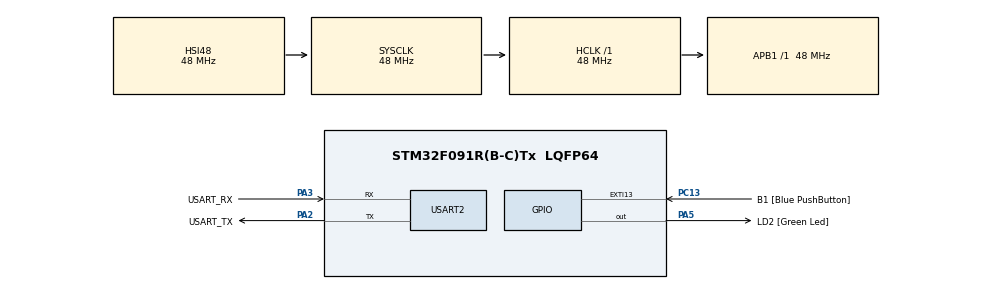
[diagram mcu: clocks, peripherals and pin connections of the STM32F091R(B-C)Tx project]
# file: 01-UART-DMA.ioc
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Dma.MEMTOMEM.1.Direction=DMA_MEMORY_TO_MEMORY
Dma.MEMTOMEM.1.Instance=DMA2_Channel1
Dma.MEMTOMEM.1.MemDataAlignment=DMA_MDATAALIGN_BYTE
Dma.MEMTOMEM.1.MemInc=DMA_MINC_ENABLE
Dma.MEMTOMEM.1.Mode=DMA_NORMAL
Dma.MEMTOMEM.1.PeriphDataAlignment=DMA_PDATAALIGN_BYTE
Dma.MEMTOMEM.1.PeriphInc=DMA_PINC_ENABLE
Dma.MEMTOMEM.1.Priority=DMA_PRIORITY_LOW
Dma.Request0=USART2_TX
Dma.Request1=MEMTOMEM
Dma.USART2_TX.0.Direction=DMA_MEMORY_TO_PERIPH
Dma.USART2_TX.0.Instance=DMA1_Channel4
Dma.USART2_TX.0.MemDataAlignment=DMA_MDATAALIGN_BYTE
Dma.USART2_TX.0.MemInc=DMA_MINC_ENABLE
Dma.USART2_TX.0.Mode=DMA_CIRCULAR
Dma.USART2_TX.0.PeriphDataAlignment=DMA_PDATAALIGN_BYTE
Dma.USART2_TX.0.PeriphInc=DMA_PINC_DISABLE
Dma.USART2_TX.0.Priority=DMA_PRIORITY_HIGH
Mcu.Family=STM32F0
Mcu.Name=STM32F091R(B-C)Tx
Mcu.Package=LQFP64
NVIC.DMA1_Ch4_7_DMA2_Ch3_5_IRQn=true\:0\:0\:false\:false\:true\:false\:true
PA13.GPIO_Label=TMS
PA13.Mode=Serial_Wire
PA13.Signal=SYS_SWDIO
PA14.GPIO_Label=TCK
PA14.Mode=Serial_Wire
PA14.Signal=SYS_SWCLK
PA2.GPIO_Label=USART_TX
PA2.GPIO_Mode=GPIO_MODE_AF_PP
PA2.GPIO_PuPd=GPIO_NOPULL
PA2.GPIO_Speed=GPIO_SPEED_FREQ_LOW
PA2.Mode=Asynchronous
PA2.Signal=USART2_TX
PA3.GPIO_Label=USART_RX
PA3.GPIO_Mode=GPIO_MODE_AF_PP
PA3.GPIO_PuPd=GPIO_NOPULL
PA3.GPIO_Speed=GPIO_SPEED_FREQ_LOW
PA3.Mode=Asynchronous
PA3.Signal=USART2_RX
PA5.GPIO_Label=LD2 [Green Led]
PA5.GPIO_Mode=GPIO_MODE_OUTPUT_PP
PA5.GPIO_PuPd=GPIO_NOPULL
PA5.GPIO_Speed=GPIO_SPEED_FREQ_LOW
PA5.Signal=GPIO_Output
PC13.GPIO_Label=B1 [Blue PushButton]
PC13.GPIO_ModeDefaultEXTI=GPIO_MODE_IT_FALLING
PC13.Signal=GPXTI13
PC14OSC32_IN.Mode=LSE-External-Oscillator
PC14OSC32_IN.Signal=RCC_OSC32_IN
PC15OSC32_OUT.Mode=LSE-External-Oscillator
PC15OSC32_OUT.Signal=RCC_OSC32_OUT
PF0-OSC_IN.Mode=HSE-External-Clock-Source
PF0-OSC_IN.Signal=RCC_OSC_IN
PF1-OSC_OUT.Signal=RCC_OSC_OUT
ProjectManager.HeapSize=0x200
ProjectManager.StackSize=0x400
ProjectManager.TargetToolchain=Makefile
RCC.AHBFreq_Value=48000000
RCC.APB1Freq_Value=48000000
RCC.APB1TimFreq_Value=48000000
RCC.FLatency-AdvancedSettings=FLASH_LATENCY_1
RCC.HCLKFreq_Value=48000000
RCC.PLLDivider=RCC_PREDIV_DIV2
RCC.PLLMUL=RCC_PLL_MUL12
RCC.PREFETCH_ENABLE-AdvancedSettings=1
RCC.SYSCLKFreq_VALUE=48000000
RCC.SYSCLKSource=RCC_SYSCLKSOURCE_HSI48
USART2.VirtualMode=VM_ASYNC
USART2.VirtualMode-Asynchronous=VM_ASYNC
board=NUCLEO-F091RC

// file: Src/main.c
/* USER CODE BEGIN Header */
/**
  ******************************************************************************
  * @file           : main.c
  * @brief          : Main program body
  ******************************************************************************
  * @attention
  *
  * <h2><center>&copy; Copyright (c) 2020 STMicroelectronics.
  * All rights reserved.</center></h2>
  *
  * This software component is licensed by ST under BSD 3-Clause license,
  * the "License"; You may not use this file except in compliance with the
  * License. You may obtain a copy of the License at:
  *                        opensource.org/licenses/BSD-3-Clause
  *
  ******************************************************************************
  */
/* USER CODE END Header */

#include "main.h"

UART_HandleTypeDef huart2;
DMA_HandleTypeDef hdma_usart2_tx;

DMA_HandleTypeDef hdma_memtomem_dma2_channel1;

void SystemClock_Config(void);
static void MX_GPIO_Init(void);
static void MX_DMA_Init(void);
static void MX_USART2_UART_Init(void);

int main(void)
{
  /* USER CODE BEGIN 1 */
  //char A[10] = "Before\r\n";
  //char B[10] = "After\r\n";
  /* USER CODE END 1 */

  /* MCU Configuration--------------------------------------------------------*/

  /* Reset of all peripherals, Initializes the Flash interface and the Systick. */
  HAL_Init();

  /* Configure the system clock */
  SystemClock_Config();

  /* Initialize all configured peripherals */
  MX_GPIO_Init();
  MX_DMA_Init();
  MX_USART2_UART_Init();

  /* Infinite loop */
  /* USER CODE BEGIN WHILE */
  char A[10] = "Before\r\n";
  char B[10] = "After\r\n";
  HAL_UART_Transmit(&huart2,(uint8_t *)A,sizeof(A),HAL_MAX_DELAY);
  HAL_DMA_Start(&hdma_memtomem_dma2_channel1,(uint32_t)&B,(uint32_t)&A,10);
  HAL_DMA_PollForTransfer(&hdma_memtomem_dma2_channel1,HAL_DMA_FULL_TRANSFER, HAL_MAX_DELAY);
  HAL_Delay(1000);
  HAL_UART_Transmit(&huart2,(uint8_t *)A,sizeof(A),HAL_MAX_DELAY);
  while (1)
  {
    // HAL_DMA_Start(&huart2.hdmatx, (uint32_t)huart2.pTxBuffPtr, (uint32_t)&huart2.Instance->TDR, strlen("\r\nf"));
    // HAL_UART_Transmit_DMA(&huart2, (uint8_t *)"\r\nf", strlen("\r\nf"));

    HAL_Delay(1000);
    /* USER CODE END WHILE */

  }
}

void SystemClock_Config(void)
{
  RCC_OscInitTypeDef RCC_OscInitStruct = {0};
  RCC_ClkInitTypeDef RCC_ClkInitStruct = {0};
  RCC_PeriphCLKInitTypeDef PeriphClkInit = {0};

  /** Initializes the CPU, AHB and APB busses clocks
  */
  RCC_OscInitStruct.OscillatorType = RCC_OSCILLATORTYPE_HSI48;
  RCC_OscInitStruct.HSI48State = RCC_HSI48_ON;
  RCC_OscInitStruct.PLL.PLLState = RCC_PLL_NONE;
  if (HAL_RCC_OscConfig(&RCC_OscInitStruct) != HAL_OK)
  {
    Error_Handler();
  }
  /** Initializes the CPU, AHB and APB busses clocks
  */
  RCC_ClkInitStruct.ClockType = RCC_CLOCKTYPE_HCLK|RCC_CLOCKTYPE_SYSCLK
                              |RCC_CLOCKTYPE_PCLK1;
  RCC_ClkInitStruct.SYSCLKSource = RCC_SYSCLKSOURCE_HSI48;
  RCC_ClkInitStruct.AHBCLKDivider = RCC_SYSCLK_DIV1;
  RCC_ClkInitStruct.APB1CLKDivider = RCC_HCLK_DIV1;

  if (HAL_RCC_ClockConfig(&RCC_ClkInitStruct, FLASH_LATENCY_1) != HAL_OK)
  {
    Error_Handler();
  }
  PeriphClkInit.PeriphClockSelection = RCC_PERIPHCLK_USART2;
  PeriphClkInit.Usart2ClockSelection = RCC_USART2CLKSOURCE_PCLK1;
  if (HAL_RCCEx_PeriphCLKConfig(&PeriphClkInit) != HAL_OK)
  {
    Error_Handler();
  }
}

static void MX_USART2_UART_Init(void)
{

  huart2.Instance = USART2;
  huart2.Init.BaudRate = 115200;
  huart2.Init.WordLength = UART_WORDLENGTH_8B;
  huart2.Init.StopBits = UART_STOPBITS_1;
  huart2.Init.Parity = UART_PARITY_NONE;
  huart2.Init.Mode = UART_MODE_TX_RX;
  huart2.Init.HwFlowCtl = UART_HWCONTROL_NONE;
  huart2.Init.OverSampling = UART_OVERSAMPLING_16;
  huart2.Init.OneBitSampling = UART_ONE_BIT_SAMPLE_DISABLE;
  huart2.AdvancedInit.AdvFeatureInit = UART_ADVFEATURE_NO_INIT;
  if (HAL_UART_Init(&huart2) != HAL_OK)
  {
    Error_Handler();
  }

}

static void MX_DMA_Init(void)
{

  /* DMA controller clock enable */
  __HAL_RCC_DMA1_CLK_ENABLE();
  __HAL_RCC_DMA2_CLK_ENABLE();

  /* Configure DMA request hdma_memtomem_dma2_channel1 on DMA2_Channel1 */
  hdma_memtomem_dma2_channel1.Instance = DMA2_Channel1;
  hdma_memtomem_dma2_channel1.Init.Direction = DMA_MEMORY_TO_MEMORY;
  hdma_memtomem_dma2_channel1.Init.PeriphInc = DMA_PINC_ENABLE;
  hdma_memtomem_dma2_channel1.Init.MemInc = DMA_MINC_ENABLE;
  hdma_memtomem_dma2_channel1.Init.PeriphDataAlignment = DMA_PDATAALIGN_BYTE;
  hdma_memtomem_dma2_channel1.Init.MemDataAlignment = DMA_MDATAALIGN_BYTE;
  hdma_memtomem_dma2_channel1.Init.Mode = DMA_NORMAL;
  hdma_memtomem_dma2_channel1.Init.Priority = DMA_PRIORITY_LOW;
  if (HAL_DMA_Init(&hdma_memtomem_dma2_channel1) != HAL_OK)
  {
    Error_Handler( );
  }

  /* DMA interrupt init */
  /* DMA1_Ch4_7_DMA2_Ch3_5_IRQn interrupt configuration */
  HAL_NVIC_SetPriority(DMA1_Ch4_7_DMA2_Ch3_5_IRQn, 0, 0);
  HAL_NVIC_EnableIRQ(DMA1_Ch4_7_DMA2_Ch3_5_IRQn);

}

static void MX_GPIO_Init(void)
{
  GPIO_InitTypeDef GPIO_InitStruct = {0};

  /* GPIO Ports Clock Enable */
  __HAL_RCC_GPIOC_CLK_ENABLE();
  __HAL_RCC_GPIOF_CLK_ENABLE();
  __HAL_RCC_GPIOA_CLK_ENABLE();

  /*Configure GPIO pin Output Level */
  HAL_GPIO_WritePin(LD2_GPIO_Port, LD2_Pin, GPIO_PIN_RESET);

  /*Configure GPIO pin : B1_Pin */
  GPIO_InitStruct.Pin = B1_Pin;
  GPIO_InitStruct.Mode = GPIO_MODE_IT_FALLING;
  GPIO_InitStruct.Pull = GPIO_NOPULL;
  HAL_GPIO_Init(B1_GPIO_Port, &GPIO_InitStruct);

  /*Configure GPIO pin : LD2_Pin */
  GPIO_InitStruct.Pin = LD2_Pin;
  GPIO_InitStruct.Mode = GPIO_MODE_OUTPUT_PP;
  GPIO_InitStruct.Pull = GPIO_NOPULL;
  GPIO_InitStruct.Speed = GPIO_SPEED_FREQ_LOW;
  HAL_GPIO_Init(LD2_GPIO_Port, &GPIO_InitStruct);

}

/* USER CODE BEGIN 4 */
void HAL_UART_TxCpltCallback(UART_HandleTypeDef *huart)
{
  HAL_GPIO_TogglePin(LD2_GPIO_Port, LD2_Pin);
}
/* USER CODE END 4 */

void Error_Handler(void)
{
}

/************************ (C) COPYRIGHT STMicroelectronics *****END OF FILE****/
